AUTOSAR XML (schema 3.1.2)
package /Components/SWC_TPM
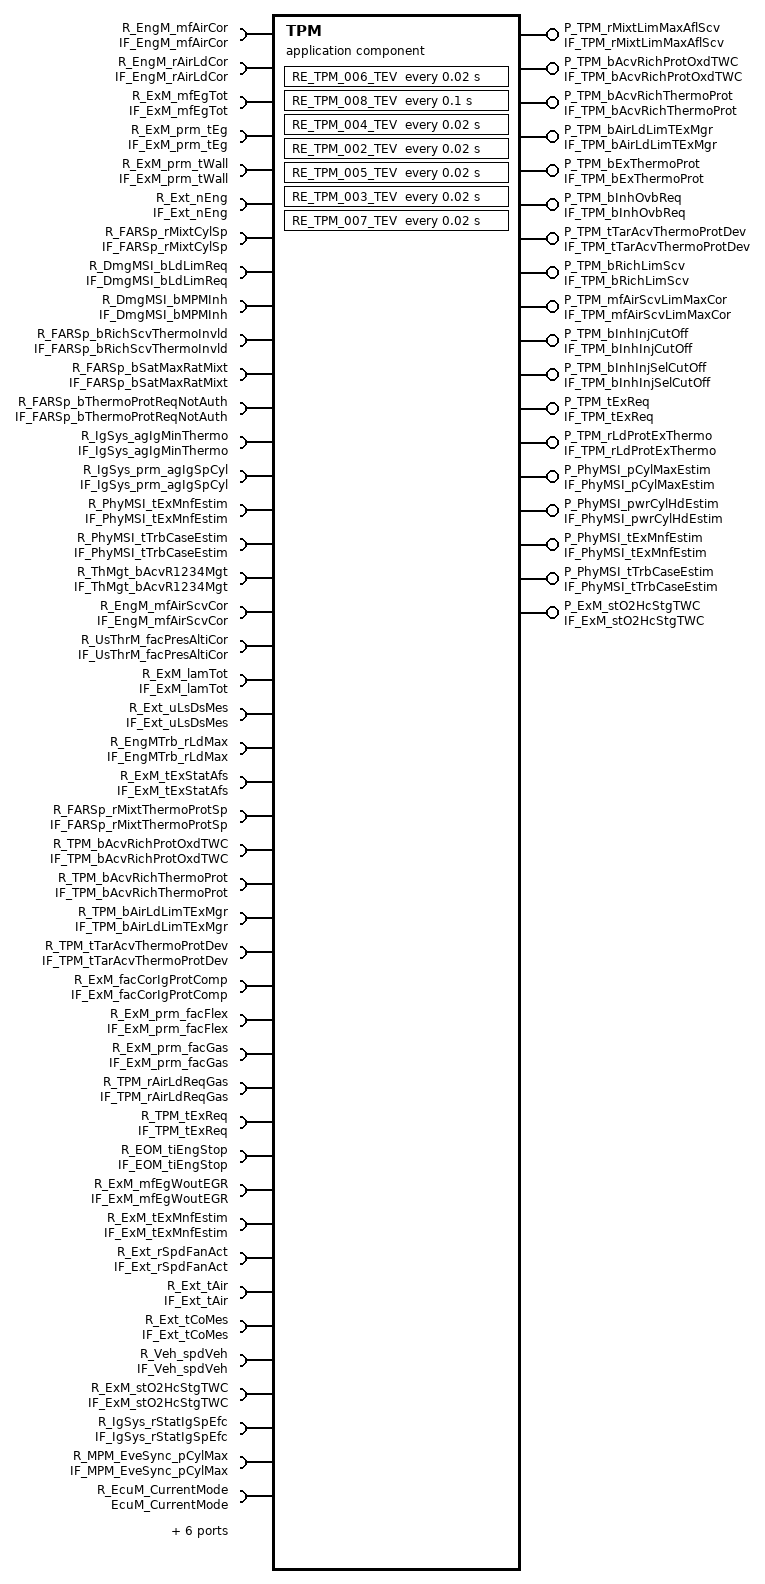
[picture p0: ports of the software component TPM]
  application software component type TPM
    50 x require port:
      R_EngM_mfAirCor: unqueued-receiver-com-spec{data-element=EngM_mfAirCor, init-value=ConstantValue, resync-time=0}, required-interface=IF_EngM_mfAirCor  # Receiver of interface IF_EngM_mfAirCor - Requirement Reference: [01552_11_02164-TPM-I002(0)]
      R_EngM_rAirLdCor: unqueued-receiver-com-spec{data-element=EngM_rAirLdCor, init-value=ConstantValue1, resync-time=0}, required-interface=IF_EngM_rAirLdCor  # Receiver of interface IF_EngM_rAirLdCor - Requirement Reference: [01552_11_02164-TPM-I003(0)]
      R_ExM_mfEgTot: unqueued-receiver-com-spec{data-element=ExM_mfEgTot, init-value=ConstantValue3, resync-time=0}, required-interface=IF_ExM_mfEgTot  # Receiver of interface IF_ExM_mfEgTot - Requirement Reference: [01552_11_02164-TPM-I004(0)]
      R_ExM_prm_tEg: unqueued-receiver-com-spec{data-element=ExM_prm_tEg, init-value=ArrayConstantValue, resync-time=0}, required-interface=IF_ExM_prm_tEg  # Receiver of interface IF_ExM_prm_tEg - Requirement Reference: [01552_11_02164-TPM-I005(0)]
      R_ExM_prm_tWall: unqueued-receiver-com-spec{data-element=ExM_prm_tWall, init-value=ArrayConstantValue5, resync-time=0}, required-interface=IF_ExM_prm_tWall  # Receiver of interface IF_ExM_prm_tWall - Requirement Reference: [01552_11_02164-TPM-I006(0)]
      R_Ext_nEng: unqueued-receiver-com-spec{data-element=Ext_nEng, init-value=ConstantValue7, resync-time=0}, required-interface=IF_Ext_nEng  # Receiver of interface IF_Ext_nEng - Requirement Reference: [01552_11_02164-TPM-I007(0)]
      R_FARSp_rMixtCylSp: unqueued-receiver-com-spec{data-element=FARSp_rMixtCylSp, init-value=ConstantValue9, resync-time=0}, required-interface=IF_FARSp_rMixtCylSp  # Receiver of interface IF_FARSp_rMixtCylSp - Requirement Reference: [01552_11_02164-TPM-I008(0)]
      R_DmgMSI_bLdLimReq: unqueued-receiver-com-spec{data-element=DmgMSI_bLdLimReq, init-value=ConstantValue11, resync-time=0}, required-interface=IF_DmgMSI_bLdLimReq  # Receiver of interface IF_DmgMSI_bLdLimReq - Requirement Reference: [01552_11_02164-TPM-I015(0)]
      R_DmgMSI_bMPMInh: unqueued-receiver-com-spec{data-element=DmgMSI_bMPMInh, init-value=ConstantValue13, resync-time=0}, required-interface=IF_DmgMSI_bMPMInh  # Receiver of interface IF_DmgMSI_bMPMInh - Requirement Reference: [01552_11_02164-TPM-I016(0)]
      R_FARSp_bRichScvThermoInvld: unqueued-receiver-com-spec{data-element=FARSp_bRichScvThermoInvld, init-value=ConstantValue15, resync-time=0}, required-interface=IF_FARSp_bRichScvThermoInvld  # Receiver of interface IF_FARSp_bRichScvThermoInvld - Requirement Reference: [01552_11_02164-TPM-I017(0)]
      R_FARSp_bSatMaxRatMixt: unqueued-receiver-com-spec{data-element=FARSp_bSatMaxRatMixt, init-value=ConstantValue17, resync-time=0}, required-interface=IF_FARSp_bSatMaxRatMixt  # Receiver of interface IF_FARSp_bSatMaxRatMixt - Requirement Reference: [01552_11_02164-TPM-I018(0)]
      R_FARSp_bThermoProtReqNotAuth: unqueued-receiver-com-spec{data-element=FARSp_bThermoProtReqNotAuth, init-value=ConstantValue19, resync-time=0}, required-interface=IF_FARSp_bThermoProtReqNotAuth  # Receiver of interface IF_FARSp_bThermoProtReqNotAuth - Requirement Reference: [01552_11_02164-TPM-I019(0)]
      R_IgSys_agIgMinThermo: unqueued-receiver-com-spec{data-element=IgSys_agIgMinThermo, init-value=ConstantValue21, resync-time=0}, required-interface=IF_IgSys_agIgMinThermo  # Receiver of interface IF_IgSys_agIgMinThermo - Requirement Reference: [01552_11_02164-TPM-I020(0)]
      R_IgSys_prm_agIgSpCyl: unqueued-receiver-com-spec{data-element=IgSys_prm_agIgSpCyl, init-value=ArrayConstantValue23, resync-time=0}, required-interface=IF_IgSys_prm_agIgSpCyl  # Receiver of interface IF_IgSys_prm_agIgSpCyl - Requirement Reference: [01552_11_02164-TPM-I021(0)]
      R_PhyMSI_tExMnfEstim: unqueued-receiver-com-spec{data-element=PhyMSI_tExMnfEstim, init-value=ConstantValue25, resync-time=0}, required-interface=IF_PhyMSI_tExMnfEstim  # Receiver of interface IF_PhyMSI_tExMnfEstim - Requirement Reference: [01552_11_02164-TPM-I022(0)]
      R_PhyMSI_tTrbCaseEstim: unqueued-receiver-com-spec{data-element=PhyMSI_tTrbCaseEstim, init-value=ConstantValue27, resync-time=0}, required-interface=IF_PhyMSI_tTrbCaseEstim  # Receiver of interface IF_PhyMSI_tTrbCaseEstim - Requirement Reference: [01552_11_02164-TPM-I023(0)]
      R_ThMgt_bAcvR1234Mgt: unqueued-receiver-com-spec{data-element=ThMgt_bAcvR1234Mgt, init-value=ConstantValue29, resync-time=0}, required-interface=IF_ThMgt_bAcvR1234Mgt  # Receiver of interface IF_ThMgt_bAcvR1234Mgt - Requirement Reference: [01552_11_02164-TPM-I024(0)]
      R_EngM_mfAirScvCor: unqueued-receiver-com-spec{data-element=EngM_mfAirScvCor, init-value=ConstantValue31, resync-time=0}, required-interface=IF_EngM_mfAirScvCor  # Receiver of interface IF_EngM_mfAirScvCor - Requirement Reference: [01552_11_02164-TPM-I027(0)]
      R_UsThrM_facPresAltiCor: unqueued-receiver-com-spec{data-element=UsThrM_facPresAltiCor, init-value=ConstantValue33, resync-time=0}, required-interface=IF_UsThrM_facPresAltiCor  # Receiver of interface IF_UsThrM_facPresAltiCor - Requirement Reference: [01552_11_02164-TPM-I028(0)]
      R_ExM_lamTot: unqueued-receiver-com-spec{data-element=ExM_lamTot, init-value=ConstantValue35, resync-time=0}, required-interface=IF_ExM_lamTot  # Receiver of interface IF_ExM_lamTot - Requirement Reference: [01552_11_02164-TPM-I031(0)]
      R_Ext_uLsDsMes: unqueued-receiver-com-spec{data-element=Ext_uLsDsMes, init-value=ConstantValue37, resync-time=0}, required-interface=IF_Ext_uLsDsMes  # Receiver of interface IF_Ext_uLsDsMes - Requirement Reference: [01552_11_02164-TPM-I032(0)]
      R_EngMTrb_rLdMax: unqueued-receiver-com-spec{data-element=EngMTrb_rLdMax, init-value=ConstantValue39, resync-time=0}, required-interface=IF_EngMTrb_rLdMax  # Receiver of interface IF_EngMTrb_rLdMax - Requirement Reference: [01552_11_02164-TPM-I035(0)]
      R_ExM_tExStatAfs: unqueued-receiver-com-spec{data-element=ExM_tExStatAfs, init-value=ConstantValue41, resync-time=0}, required-interface=IF_ExM_tExStatAfs  # Receiver of interface IF_ExM_tExStatAfs - Requirement Reference: [01552_11_02164-TPM-I036(1)]
      R_FARSp_rMixtThermoProtSp: unqueued-receiver-com-spec{data-element=FARSp_rMixtThermoProtSp, init-value=ConstantValue43, resync-time=0}, required-interface=IF_FARSp_rMixtThermoProtSp  # Receiver of interface IF_FARSp_rMixtThermoProtSp - Requirement Reference: [01552_11_02164-TPM-I037(0)]
      R_TPM_bAcvRichProtOxdTWC: unqueued-receiver-com-spec{data-element=TPM_bAcvRichProtOxdTWC, init-value=ConstantValue45, resync-time=0}, required-interface=IF_TPM_bAcvRichProtOxdTWC  # Receiver of interface IF_TPM_bAcvRichProtOxdTWC - Requirement Reference: [01552_11_02164-TPM-I038(0)]
      R_TPM_bAcvRichThermoProt: unqueued-receiver-com-spec{data-element=TPM_bAcvRichThermoProt, init-value=ConstantValue47, resync-time=0}, required-interface=IF_TPM_bAcvRichThermoProt  # Receiver of interface IF_TPM_bAcvRichThermoProt - Requirement Reference: [01552_11_02164-TPM-I039(0)]
      R_TPM_bAirLdLimTExMgr: unqueued-receiver-com-spec{data-element=TPM_bAirLdLimTExMgr, init-value=ConstantValue49, resync-time=0}, required-interface=IF_TPM_bAirLdLimTExMgr  # Receiver of interface IF_TPM_bAirLdLimTExMgr - Requirement Reference: [01552_11_02164-TPM-I040(0)]
      R_TPM_tTarAcvThermoProtDev: unqueued-receiver-com-spec{data-element=TPM_tTarAcvThermoProtDev, init-value=ConstantValue51, resync-time=0}, required-interface=IF_TPM_tTarAcvThermoProtDev  # Receiver of interface IF_TPM_tTarAcvThermoProtDev - Requirement Reference: [01552_11_02164-TPM-I041(1)]
      R_ExM_facCorIgProtComp: unqueued-receiver-com-spec{data-element=ExM_facCorIgProtComp, init-value=ConstantValue53, resync-time=0}, required-interface=IF_ExM_facCorIgProtComp  # Receiver of interface IF_ExM_facCorIgProtComp - Requirement Reference: [01552_11_02164-TPM-I043(0)]
      R_ExM_prm_facFlex: unqueued-receiver-com-spec{data-element=ExM_prm_facFlex, init-value=ArrayConstantValue55, resync-time=0}, required-interface=IF_ExM_prm_facFlex  # Receiver of interface IF_ExM_prm_facFlex - Requirement Reference: [01552_11_02164-TPM-I045(0)]
      R_ExM_prm_facGas: unqueued-receiver-com-spec{data-element=ExM_prm_facGas, init-value=ArrayConstantValue57, resync-time=0}, required-interface=IF_ExM_prm_facGas  # Receiver of interface IF_ExM_prm_facGas - Requirement Reference: [01552_11_02164-TPM-I046(0)]
      R_TPM_rAirLdReqGas: unqueued-receiver-com-spec{data-element=TPM_rAirLdReqGas, init-value=ConstantValue59, resync-time=0}, required-interface=IF_TPM_rAirLdReqGas  # Receiver of interface IF_TPM_rAirLdReqGas - Requirement Reference: [01552_11_02164-TPM-I050(0)]
      R_TPM_tExReq: unqueued-receiver-com-spec{data-element=TPM_tExReq, init-value=ConstantValue61, resync-time=0}, required-interface=IF_TPM_tExReq  # Receiver of interface IF_TPM_tExReq - Requirement Reference: [01552_11_02164-TPM-I051(1)]
      R_EOM_tiEngStop: unqueued-receiver-com-spec{data-element=EOM_tiEngStop, init-value=ConstantValue63, resync-time=0}, required-interface=IF_EOM_tiEngStop  # Receiver of interface IF_EOM_tiEngStop - Requirement Reference: [01552_11_02164-TPM-I056(0)]
      R_ExM_mfEgWoutEGR: unqueued-receiver-com-spec{data-element=ExM_mfEgWoutEGR, init-value=ConstantValue65, resync-time=0}, required-interface=IF_ExM_mfEgWoutEGR  # Receiver of interface IF_ExM_mfEgWoutEGR - Requirement Reference: [01552_11_02164-TPM-I057(0)]
      R_ExM_tExMnfEstim: unqueued-receiver-com-spec{data-element=ExM_tExMnfEstim, init-value=ConstantValue67, resync-time=0}, required-interface=IF_ExM_tExMnfEstim  # Receiver of interface IF_ExM_tExMnfEstim - Requirement Reference: [01552_11_02164-TPM-I058(0)]
      R_Ext_rSpdFanAct: unqueued-receiver-com-spec{data-element=Ext_rSpdFanAct, init-value=ConstantValue69, resync-time=0}, required-interface=IF_Ext_rSpdFanAct  # Receiver of interface IF_Ext_rSpdFanAct - Requirement Reference: [01552_11_02164-TPM-I059(0)]
      R_Ext_tAir: unqueued-receiver-com-spec{data-element=Ext_tAir, init-value=ConstantValue71, resync-time=0}, required-interface=IF_Ext_tAir  # Receiver of interface IF_Ext_tAir - Requirement Reference: [01552_11_02164-TPM-I060(0)]
      R_Ext_tCoMes: unqueued-receiver-com-spec{data-element=Ext_tCoMes, init-value=ConstantValue73, resync-time=0}, required-interface=IF_Ext_tCoMes  # Receiver of interface IF_Ext_tCoMes - Requirement Reference: [01552_11_02164-TPM-I061(0)]
      R_Veh_spdVeh: unqueued-receiver-com-spec{data-element=Veh_spdVeh, init-value=ConstantValue75, resync-time=0}, required-interface=IF_Veh_spdVeh  # Receiver of interface IF_Veh_spdVeh - Requirement Reference: [01552_11_02164-TPM-I062(0)]
      R_ExM_stO2HcStgTWC: unqueued-receiver-com-spec{data-element=ExM_stO2HcStgTWC, init-value=ConstantValue77, resync-time=0}, required-interface=IF_ExM_stO2HcStgTWC  # Receiver of interface IF_ExM_stO2HcStgTWC - Requirement Reference: [01552_11_02164-TPM-I083(0)]
      R_IgSys_rStatIgSpEfc: unqueued-receiver-com-spec{data-element=IgSys_rStatIgSpEfc, init-value=ConstantValue79, resync-time=0}, required-interface=IF_IgSys_rStatIgSpEfc  # Receiver of interface IF_IgSys_rStatIgSpEfc - Requirement Reference: [01552_11_02164-TPM-I085(0)]
      R_MPM_EveSync_pCylMax: unqueued-receiver-com-spec{data-element=MPM_EveSync_pCylMax, init-value=ConstantValue81, resync-time=0}, required-interface=IF_MPM_EveSync_pCylMax  # Receiver of interface IF_MPM_EveSync_pCylMax - Requirement Reference: [01552_11_02164-TPM-I086(0)]
      R_EcuM_CurrentMode: required-interface=EcuM_CurrentMode
      R_UCE_stWkuMainRelSt: required-interface=IF_UCE_stWkuMainRelSt
      R_FRM_bAcvEcpHeatProt: required-interface=FunctionInhibition  # 01552_11_02164-TPM-I076(0)
      R_FRM_bAcvTPMDecTMaxDev: required-interface=FunctionInhibition  # 01552_11_02164-TPM-I077(0)
      R_FRM_bAcvLimScv: required-interface=FunctionInhibition  # 01552_11_02164-TPM-I078(0)
      R_FRM_bAcvTPMInhLsTWCSt: required-interface=FunctionInhibition  # 01552_11_02164-TPM-I079(0)
      R_FRM_bInhCutOff: required-interface=FunctionInhibition  # 01552_11_02164-TPM-I080(0)
    18 x provide port:
      P_TPM_rMixtLimMaxAflScv: unqueued-sender-com-spec{data-element=TPM_rMixtLimMaxAflScv, can-invalidate=false, init-value=ConstantValue83}, provided-interface=IF_TPM_rMixtLimMaxAflScv
      P_TPM_bAcvRichProtOxdTWC: unqueued-sender-com-spec{data-element=TPM_bAcvRichProtOxdTWC, can-invalidate=false, init-value=ConstantValue85}, provided-interface=IF_TPM_bAcvRichProtOxdTWC
      P_TPM_bAcvRichThermoProt: unqueued-sender-com-spec{data-element=TPM_bAcvRichThermoProt, can-invalidate=false, init-value=ConstantValue87}, provided-interface=IF_TPM_bAcvRichThermoProt
      P_TPM_bAirLdLimTExMgr: unqueued-sender-com-spec{data-element=TPM_bAirLdLimTExMgr, can-invalidate=false, init-value=ConstantValue89}, provided-interface=IF_TPM_bAirLdLimTExMgr
      P_TPM_bExThermoProt: unqueued-sender-com-spec{data-element=TPM_bExThermoProt, can-invalidate=false, init-value=ConstantValue91}, provided-interface=IF_TPM_bExThermoProt
      P_TPM_bInhOvbReq: unqueued-sender-com-spec{data-element=TPM_bInhOvbReq, can-invalidate=false, init-value=ConstantValue93}, provided-interface=IF_TPM_bInhOvbReq
      P_TPM_tTarAcvThermoProtDev: unqueued-sender-com-spec{data-element=TPM_tTarAcvThermoProtDev, can-invalidate=false, init-value=TPM_tTarAcvThermoProtDev_Cst}, provided-interface=IF_TPM_tTarAcvThermoProtDev
      P_TPM_bRichLimScv: unqueued-sender-com-spec{data-element=TPM_bRichLimScv, can-invalidate=false, init-value=ConstantValue95}, provided-interface=IF_TPM_bRichLimScv
      P_TPM_mfAirScvLimMaxCor: unqueued-sender-com-spec{data-element=TPM_mfAirScvLimMaxCor, can-invalidate=false, init-value=TPM_mfAirScvLimMaxCor_Cst}, provided-interface=IF_TPM_mfAirScvLimMaxCor
      P_TPM_bInhInjCutOff: unqueued-sender-com-spec{data-element=TPM_bInhInjCutOff, can-invalidate=false, init-value=TPM_bInhInjCutOff_Cst}, provided-interface=IF_TPM_bInhInjCutOff
      P_TPM_bInhInjSelCutOff: unqueued-sender-com-spec{data-element=TPM_bInhInjSelCutOff, can-invalidate=false, init-value=TPM_bInhInjSelCutOff_Cst}, provided-interface=IF_TPM_bInhInjSelCutOff
      P_TPM_tExReq: unqueued-sender-com-spec{data-element=TPM_tExReq, can-invalidate=false, init-value=ConstantValue97}, provided-interface=IF_TPM_tExReq
      P_TPM_rLdProtExThermo: unqueued-sender-com-spec{data-element=TPM_rLdProtExThermo, can-invalidate=false, init-value=ConstantValue99}, provided-interface=IF_TPM_rLdProtExThermo
      P_PhyMSI_pCylMaxEstim: unqueued-sender-com-spec{data-element=PhyMSI_pCylMaxEstim, can-invalidate=false, init-value=ConstantValue101}, provided-interface=IF_PhyMSI_pCylMaxEstim
      P_PhyMSI_pwrCylHdEstim: unqueued-sender-com-spec{data-element=PhyMSI_pwrCylHdEstim, can-invalidate=false, init-value=ConstantValue103}, provided-interface=IF_PhyMSI_pwrCylHdEstim
      P_PhyMSI_tExMnfEstim: unqueued-sender-com-spec{data-element=PhyMSI_tExMnfEstim, can-invalidate=false, init-value=ConstantValue105}, provided-interface=IF_PhyMSI_tExMnfEstim
      P_PhyMSI_tTrbCaseEstim: unqueued-sender-com-spec{data-element=PhyMSI_tTrbCaseEstim, can-invalidate=false, init-value=ConstantValue107}, provided-interface=IF_PhyMSI_tTrbCaseEstim
      P_ExM_stO2HcStgTWC: unqueued-sender-com-spec{data-element=ExM_stO2HcStgTWC, can-invalidate=false, init-value=ConstantValue109}, provided-interface=IF_ExM_stO2HcStgTWC
  69 x constant specification:
    ArrayConstantValue
      value:
        array specification ArrayConstantValue: type=rt_Array_UInt16_12_m0
          12 x integer literal, all with type=DT_ExM_prm_tEg, value=0:
            Const
            Const{1..11}
    ArrayConstantValue23
      value:
        array specification ArrayConstantValue23: type=rt_Array_UInt8_6_m1
          6 x integer literal, all with type=DT_IgSys_prm_agIgSpCyl, value=96:
            Const
            Const{1..5}
    ArrayConstantValue5
      value:
        array specification ArrayConstantValue5: type=rt_Array_UInt16_12_m1
          12 x integer literal, all with type=DT_ExM_prm_tWall, value=0:
            Const
            Const{1..11}
    ArrayConstantValue55
      value:
        array specification ArrayConstantValue55: type=rt_Array_UInt16_5_m0
          5 x integer literal, all with type=DT_ExM_prm_facFlex, value=0:
            Const
            Const{1..4}
    ArrayConstantValue57
      value:
        array specification ArrayConstantValue57: type=Array_5_UInt16
          5 x integer literal, all with type=DT_ExM_prm_facGas, value=0:
            Const
            Const{1..4}
    ConstantValue
      value:
        integer literal ConstantValue: type=DT_EngM_mfAirCor, value=0
    ConstantValue1
      value:
        integer literal ConstantValue1: type=DT_EngM_rAirLdCor, value=0
    ConstantValue101
      value:
        integer literal ConstantValue101: type=DT_PhyMSI_pCylMaxEstim, value=0
    ConstantValue103
      value:
        integer literal ConstantValue103: type=DT_PhyMSI_pwrCylHdEstim, value=0
    ConstantValue105
      value:
        integer literal ConstantValue105: type=DT_PhyMSI_tExMnfEstim, value=7136
    ConstantValue107
      value:
        integer literal ConstantValue107: type=DT_PhyMSI_tTrbCaseEstim, value=7136
    ConstantValue109
      value:
        integer literal ConstantValue109: type=DT_ExM_stO2HcStgTWC, value=0
    ConstantValue11
      value:
        boolean literal ConstantValue11: type=DT_DmgMSI_bLdLimReq, value=false
    ConstantValue13
      value:
        boolean literal ConstantValue13: type=DT_DmgMSI_bMPMInh, value=false
    ConstantValue15
      value:
        boolean literal ConstantValue15: type=DT_FARSp_bRichScvThermoInvld, value=false
    ConstantValue17
      value:
        boolean literal ConstantValue17: type=DT_FARSp_bSatMaxRatMixt, value=false
    ConstantValue19
      value:
        boolean literal ConstantValue19: type=DT_FARSp_bThermoProtReqNotAuth, value=false
    ConstantValue21
      value:
        integer literal ConstantValue21: type=DT_IgSys_agIgMinThermo, value=96
    ConstantValue25
      value:
        integer literal ConstantValue25: type=DT_PhyMSI_tExMnfEstim, value=7136
    ConstantValue27
      value:
        integer literal ConstantValue27: type=DT_PhyMSI_tTrbCaseEstim, value=7136
    ConstantValue29
      value:
        boolean literal ConstantValue29: type=DT_ThMgt_bAcvR1234Mgt, value=false
    ConstantValue3
      value:
        integer literal ConstantValue3: type=DT_ExM_mfEgTot, value=0
    ConstantValue31
      value:
        integer literal ConstantValue31: type=DT_EngM_mfAirScvCor, value=0
    ConstantValue33
      value:
        integer literal ConstantValue33: type=DT_UsThrM_facPresAltiCor, value=0
    ConstantValue35
      value:
        integer literal ConstantValue35: type=DT_ExM_lamTot, value=8192
    ConstantValue37
      value:
        integer literal ConstantValue37: type=DT_Ext_uLsDsMes, value=0
    ConstantValue39
      value:
        integer literal ConstantValue39: type=DT_EngMTrb_rLdMax, value=0
    ConstantValue41
      value:
        integer literal ConstantValue41: type=DT_ExM_tExStatAfs, value=4800
    ConstantValue43
      value:
        integer literal ConstantValue43: type=DT_FARSp_rMixtThermoProtSp, value=0
    ConstantValue45
      value:
        boolean literal ConstantValue45: type=DT_TPM_bAcvRichProtOxdTWC, value=false
    ConstantValue47
      value:
        boolean literal ConstantValue47: type=DT_TPM_bAcvRichThermoProt, value=false
    ConstantValue49
      value:
        boolean literal ConstantValue49: type=DT_TPM_bAirLdLimTExMgr, value=false
    ConstantValue51
      value:
        integer literal ConstantValue51: type=DT_TPM_tTarAcvThermoProtDev, value=7136
    ConstantValue53
      value:
        integer literal ConstantValue53: type=DT_ExM_facCorIgProtComp, value=16384
    ConstantValue59
      value:
        integer literal ConstantValue59: type=DT_TPM_rAirLdReqGas, value=49152
    ConstantValue61
      value:
        integer literal ConstantValue61: type=DT_TPM_tExReq, value=7136
    ConstantValue63
      value:
        integer literal ConstantValue63: type=DT_EOM_tiEngStop, value=864000
    ConstantValue65
      value:
        integer literal ConstantValue65: type=DT_ExM_mfEgWoutEGR, value=0
    ConstantValue67
      value:
        integer literal ConstantValue67: type=DT_ExM_tExMnfEstim, value=4800
    ConstantValue69
      value:
        integer literal ConstantValue69: type=DT_Ext_rSpdFanAct, value=0
    ConstantValue7
      value:
        integer literal ConstantValue7: type=DT_Ext_nEng, value=0
    ConstantValue71
      value:
        integer literal ConstantValue71: type=DT_Ext_tAir, value=20
    ConstantValue73
      value:
        integer literal ConstantValue73: type=DT_Ext_tCoMes, value=20
    ConstantValue75
      value:
        integer literal ConstantValue75: type=DT_Veh_spdVeh, value=0
    ConstantValue77
      value:
        integer literal ConstantValue77: type=DT_ExM_stO2HcStgTWC, value=0
    ConstantValue79
      value:
        integer literal ConstantValue79: type=DT_IgSys_rStatIgSpEfc, value=0
    ConstantValue81
      value:
        boolean literal ConstantValue81: type=DT_MPM_EveSync_pCylMax, value=false
    ConstantValue83
      value:
        integer literal ConstantValue83: type=DT_TPM_rMixtLimMaxAflScv, value=0
    ConstantValue85
      value:
        boolean literal ConstantValue85: type=DT_TPM_bAcvRichProtOxdTWC, value=false
    ConstantValue87
      value:
        boolean literal ConstantValue87: type=DT_TPM_bAcvRichThermoProt, value=false
    ConstantValue89
      value:
        boolean literal ConstantValue89: type=DT_TPM_bAirLdLimTExMgr, value=false
    ConstantValue9
      value:
        integer literal ConstantValue9: type=DT_FARSp_rMixtCylSp, value=4096
    ConstantValue91
      value:
        boolean literal ConstantValue91: type=DT_TPM_bExThermoProt, value=false
    ConstantValue93
      value:
        boolean literal ConstantValue93: type=DT_TPM_bInhOvbReq, value=false
    ConstantValue95
      value:
        boolean literal ConstantValue95: type=DT_TPM_bRichLimScv, value=false
    ConstantValue97
      value:
        integer literal ConstantValue97: type=DT_TPM_tExReq, value=7136
    ConstantValue99
      value:
        integer literal ConstantValue99: type=DT_TPM_rLdProtExThermo, value=0
    TPM_bAcvProtExScv_Cst
      value:
        boolean literal TPM_bAcvProtExScv_Cst: type=DT_TPM_bAcvProtExScv, value=false
    TPM_bInhInjCutOff_Cst
      value:
        boolean literal TPM_bInhInjCutOff_Cst: type=DT_TPM_bInhInjCutOff, value=false
    TPM_bInhInjSelCutOff_Cst
      value:
        boolean literal TPM_bInhInjSelCutOff_Cst: type=DT_TPM_bInhInjSelCutOff, value=false
    TPM_mfAirScvLimMax_Cst
      value:
        integer literal TPM_mfAirScvLimMax_Cst: type=DT_TPM_mfAirScvLimMax, value=0
    TPM_mfAirScvLimMaxCor_Cst
      value:
        integer literal TPM_mfAirScvLimMaxCor_Cst: type=DT_TPM_mfAirScvLimMaxCor, value=0
    TPM_noAcvThermoProtDev_Cst
      value:
        integer literal TPM_noAcvThermoProtDev_Cst: type=DT_TPM_noAcvThermoProtDev, value=0
    TPM_rAirLdReq_Cst
      value:
        integer literal TPM_rAirLdReq_Cst: type=DT_TPM_rAirLdReq, value=0
    TPM_rAirLdReqRbl_Cst
      value:
        integer literal TPM_rAirLdReqRbl_Cst: type=DT_TPM_rAirLdReqRbl, value=0
    TPM_tExCurAcvThermoProtDev_Cst
      value:
        integer literal TPM_tExCurAcvThermoProtDev_Cst: type=DT_TPM_tExCurAcvThermoProtDev, value=0
    TPM_tRefTWCScvMax_Cst
      value:
        integer literal TPM_tRefTWCScvMax_Cst: type=DT_TPM_tRefTWCScvMax, value=0
    TPM_tTarAcvThermoProtDev_Cst
      value:
        integer literal TPM_tTarAcvThermoProtDev_Cst: type=DT_TPM_tTarAcvThermoProtDev, value=7136
    TPM_tTWC_Cst
      value:
        integer literal TPM_tTWC_Cst: type=DT_TPM_tTWC, value=0
  internal behavior IB_TPM: component=TPM
    timing event EV_TPM_006_TEV: mode-dependency=dependent-on-mode=[R_UCE_stWkuMainRelSt.RCD_stWkuMainRelSt.Invalid, R_UCE_stWkuMainRelSt.RCD_stWkuMainRelSt.PostMainWakeUp, R_UCE_stWkuMainRelSt.RCD_stWkuMainRelSt.PreMainWakeUp], start-on-event=RE_TPM_006_TEV, period=0.02
    timing event EV_TPM_008_TEV: mode-dependency=dependent-on-mode=[R_UCE_stWkuMainRelSt.RCD_stWkuMainRelSt.Invalid, R_UCE_stWkuMainRelSt.RCD_stWkuMainRelSt.PostMainWakeUp, R_UCE_stWkuMainRelSt.RCD_stWkuMainRelSt.PreMainWakeUp], start-on-event=RE_TPM_008_TEV, period=0.1
    data received event EV_TPM_009_DRE: start-on-event=RE_TPM_009_DRE, data=R_MPM_EveSync_pCylMax.MPM_EveSync_pCylMax
    timing event EV_TPM_004_TEV: mode-dependency=dependent-on-mode=[R_UCE_stWkuMainRelSt.RCD_stWkuMainRelSt.Invalid, R_UCE_stWkuMainRelSt.RCD_stWkuMainRelSt.PostMainWakeUp, R_UCE_stWkuMainRelSt.RCD_stWkuMainRelSt.PreMainWakeUp], start-on-event=RE_TPM_004_TEV, period=0.02
    timing event EV_TPM_002_TEV: mode-dependency=dependent-on-mode=[R_UCE_stWkuMainRelSt.RCD_stWkuMainRelSt.Invalid, R_UCE_stWkuMainRelSt.RCD_stWkuMainRelSt.PostMainWakeUp, R_UCE_stWkuMainRelSt.RCD_stWkuMainRelSt.PreMainWakeUp], start-on-event=RE_TPM_002_TEV, period=0.02
    timing event EV_TPM_005_TEV: mode-dependency=dependent-on-mode=[R_UCE_stWkuMainRelSt.RCD_stWkuMainRelSt.Invalid, R_UCE_stWkuMainRelSt.RCD_stWkuMainRelSt.PostMainWakeUp, R_UCE_stWkuMainRelSt.RCD_stWkuMainRelSt.PreMainWakeUp], start-on-event=RE_TPM_005_TEV, period=0.02
    mode switch event EV_TPM_001_MSE: start-on-event=RE_TPM_001_MSE, activation=ENTRY, mode=R_EcuM_CurrentMode.currentMode.RUN
    timing event EV_TPM_003_TEV: mode-dependency=dependent-on-mode=[R_UCE_stWkuMainRelSt.RCD_stWkuMainRelSt.Invalid, R_UCE_stWkuMainRelSt.RCD_stWkuMainRelSt.PostMainWakeUp, R_UCE_stWkuMainRelSt.RCD_stWkuMainRelSt.PreMainWakeUp], start-on-event=RE_TPM_003_TEV, period=0.02
    timing event EV_TPM_007_TEV: mode-dependency=dependent-on-mode=[R_UCE_stWkuMainRelSt.RCD_stWkuMainRelSt.Invalid, R_UCE_stWkuMainRelSt.RCD_stWkuMainRelSt.PostMainWakeUp, R_UCE_stWkuMainRelSt.RCD_stWkuMainRelSt.PreMainWakeUp], start-on-event=RE_TPM_007_TEV, period=0.02
    8 x inter runnable variable, all with sw-calibration-access=READ-WRITE, communication-approach=EXPLICIT:
      TPM_tExCurAcvThermoProtDev: type=DT_TPM_tExCurAcvThermoProtDev, init-value=TPM_tExCurAcvThermoProtDev_Cst  # [01552_11_02164-TPM-I066(0)] - In danger element's temperature
      TPM_mfAirScvLimMax: type=DT_TPM_mfAirScvLimMax, init-value=TPM_mfAirScvLimMax_Cst  # [01552_11_02164-TPM-I063(0)] - Maximum scavenging air mass flow for three way catalyst thermal and oxydation protection
      TPM_rAirLdReqRbl: type=DT_TPM_rAirLdReqRbl, init-value=TPM_rAirLdReqRbl_Cst  # [01552_11_02164-TPM-I069(0)] - Air load limitation due to rumble risk
      TPM_tTWC: type=DT_TPM_tTWC, init-value=TPM_tTWC_Cst  # [01552_11_02164-TPM-I067(0)] - Catalyst's temperature
      TPM_noAcvThermoProtDev: type=DT_TPM_noAcvThermoProtDev, init-value=TPM_noAcvThermoProtDev_Cst  # [01552_11_02164-TPM-I065(0)] - In danger element's identification number
      TPM_rAirLdReq: type=DT_TPM_rAirLdReq, init-value=TPM_rAirLdReq_Cst  # [01552_11_02164-TPM-I070(0)] - Air Load limitation due to component protection
      TPM_bAcvProtExScv: type=DT_TPM_bAcvProtExScv, init-value=TPM_bAcvProtExScv_Cst  # [01552_11_02164-TPM-I068(0)] - Boolean indicating the activation of scavenging inhibition
      TPM_tRefTWCScvMax: type=DT_TPM_tRefTWCScvMax, init-value=TPM_tRefTWCScvMax_Cst  # [01552_11_02164-TPM-I064(0)] - Reference TWC temperature for maximum scavenging air mass flow limitation
    9 x runnable:
      RE_TPM_003_TEV: written-variable=[TPM_noAcvThermoProtDev, TPM_tExCurAcvThermoProtDev, TPM_tTWC]  # 01552_11_02164-TPM-A003(0)
        13 x data receive point:
          dr_ThMgt_bAcvR1234Mgt: data-element=R_ThMgt_bAcvR1234Mgt.ThMgt_bAcvR1234Mgt
          dr_PhyMSI_tTrbCaseEstim: data-element=R_PhyMSI_tTrbCaseEstim.PhyMSI_tTrbCaseEstim
          dr_PhyMSI_tExMnfEstim: data-element=R_PhyMSI_tExMnfEstim.PhyMSI_tExMnfEstim
          dr_FARSp_rMixtCylSp: data-element=R_FARSp_rMixtCylSp.FARSp_rMixtCylSp
          dr_DmgMSI_bMPMInh: data-element=R_DmgMSI_bMPMInh.DmgMSI_bMPMInh
          dr_ExM_prm_tEg: data-element=R_ExM_prm_tEg.ExM_prm_tEg
          dr_FARSp_bRichScvThermoInvld: data-element=R_FARSp_bRichScvThermoInvld.FARSp_bRichScvThermoInvld
          dr_ExM_prm_tWall: data-element=R_ExM_prm_tWall.ExM_prm_tWall
          dr_FARSp_bSatMaxRatMixt: data-element=R_FARSp_bSatMaxRatMixt.FARSp_bSatMaxRatMixt
          dr_IgSys_agIgMinThermo: data-element=R_IgSys_agIgMinThermo.IgSys_agIgMinThermo
          dr_FARSp_bThermoProtReqNotAuth: data-element=R_FARSp_bThermoProtReqNotAuth.FARSp_bThermoProtReqNotAuth
          dr_DmgMSI_bLdLimReq: data-element=R_DmgMSI_bLdLimReq.DmgMSI_bLdLimReq
          dr_IgSys_prm_agIgSpCyl: data-element=R_IgSys_prm_agIgSpCyl.IgSys_prm_agIgSpCyl
        6 x data send point:
          ds_TPM_bInhOvbReq: data-element=P_TPM_bInhOvbReq.TPM_bInhOvbReq
          ds_TPM_bAcvRichThermoProt: data-element=P_TPM_bAcvRichThermoProt.TPM_bAcvRichThermoProt
          ds_TPM_bAcvRichProtOxdTWC: data-element=P_TPM_bAcvRichProtOxdTWC.TPM_bAcvRichProtOxdTWC
          ds_TPM_bAirLdLimTExMgr: data-element=P_TPM_bAirLdLimTExMgr.TPM_bAirLdLimTExMgr
          ds_TPM_tTarAcvThermoProtDev: data-element=P_TPM_tTarAcvThermoProtDev.TPM_tTarAcvThermoProtDev
          ds_TPM_bExThermoProt: data-element=P_TPM_bExThermoProt.TPM_bExThermoProt
        sync call SC_FRM_bAcvEcpHeatProt: operation=R_FRM_bAcvEcpHeatProt.GetFunctionPermission
        sync call SC_FRM_bAcvTPMDecTMaxDev: operation=R_FRM_bAcvTPMDecTMaxDev.GetFunctionPermission
      RE_TPM_005_TEV: read-variable=TPM_tTWC  # 01552_11_02164-TPM-A005(0)
        5 x data receive point:
          dr_EngM_mfAirCor: data-element=R_EngM_mfAirCor.EngM_mfAirCor
          dr_EngM_mfAirScvCor: data-element=R_EngM_mfAirScvCor.EngM_mfAirScvCor
          dr_FARSp_rMixtCylSp: data-element=R_FARSp_rMixtCylSp.FARSp_rMixtCylSp
          dr_ExM_lamTot: data-element=R_ExM_lamTot.ExM_lamTot
          dr_Ext_uLsDsMes: data-element=R_Ext_uLsDsMes.Ext_uLsDsMes
        data send point ds_TPM_bInhInjCutOff: data-element=P_TPM_bInhInjCutOff.TPM_bInhInjCutOff
        data send point ds_TPM_bInhInjSelCutOff: data-element=P_TPM_bInhInjSelCutOff.TPM_bInhInjSelCutOff
        data send point ds_ExM_stO2HcStgTWC: data-element=P_ExM_stO2HcStgTWC.ExM_stO2HcStgTWC
        sync call SC_FRM_bInhCutOff: operation=R_FRM_bInhCutOff.GetFunctionPermission
        sync call SC_FRM_bAcvTPMDecTMaxDev: operation=R_FRM_bAcvTPMDecTMaxDev.GetFunctionPermission
        sync call SC_FRM_bAcvTPMInhLsTWCSt: operation=R_FRM_bAcvTPMInhLsTWCSt.GetFunctionPermission
      RE_TPM_002_TEV: written-variable=[TPM_tRefTWCScvMax, TPM_mfAirScvLimMax]  # 01552_11_02164-TPM-A002(0)
        8 x data receive point:
          dr_EngM_rAirLdCor: data-element=R_EngM_rAirLdCor.EngM_rAirLdCor
          dr_ExM_prm_tWall: data-element=R_ExM_prm_tWall.ExM_prm_tWall
          dr_FARSp_rMixtCylSp: data-element=R_FARSp_rMixtCylSp.FARSp_rMixtCylSp
          dr_ExM_prm_tEg: data-element=R_ExM_prm_tEg.ExM_prm_tEg
          dr_EngM_mfAirCor: data-element=R_EngM_mfAirCor.EngM_mfAirCor
          dr_ExM_mfEgTot: data-element=R_ExM_mfEgTot.ExM_mfEgTot
          dr_ExM_stO2HcStgTWC: data-element=R_ExM_stO2HcStgTWC.ExM_stO2HcStgTWC
          dr_Ext_nEng: data-element=R_Ext_nEng.Ext_nEng
        data send point ds_TPM_rMixtLimMaxAflScv: data-element=P_TPM_rMixtLimMaxAflScv.TPM_rMixtLimMaxAflScv
      RE_TPM_004_TEV: read-variable=[TPM_mfAirScvLimMax, TPM_tRefTWCScvMax], written-variable=[TPM_bAcvProtExScv, TPM_rAirLdReqRbl]  # 01552_11_02164-TPM-A004(0)
        6 x data receive point:
          dr_EngM_rAirLdCor: data-element=R_EngM_rAirLdCor.EngM_rAirLdCor
          dr_ExM_stO2HcStgTWC: data-element=R_ExM_stO2HcStgTWC.ExM_stO2HcStgTWC
          dr_EngM_mfAirScvCor: data-element=R_EngM_mfAirScvCor.EngM_mfAirScvCor
          dr_UsThrM_facPresAltiCor: data-element=R_UsThrM_facPresAltiCor.UsThrM_facPresAltiCor
          dr_Ext_nEng: data-element=R_Ext_nEng.Ext_nEng
          dr_FARSp_bRichScvThermoInvld: data-element=R_FARSp_bRichScvThermoInvld.FARSp_bRichScvThermoInvld
        data send point ds_TPM_mfAirScvLimMaxCor: data-element=P_TPM_mfAirScvLimMaxCor.TPM_mfAirScvLimMaxCor
        data send point ds_TPM_bRichLimScv: data-element=P_TPM_bRichLimScv.TPM_bRichLimScv
        sync call SC_FRM_bAcvTPMDecTMaxDev: operation=R_FRM_bAcvTPMDecTMaxDev.GetFunctionPermission
        sync call SC_FRM_bAcvLimScv: operation=R_FRM_bAcvLimScv.GetFunctionPermission
      RE_TPM_008_TEV  # 01552_11_02164-TPM-A008(1)
        9 x data receive point:
          dr_Ext_tAir: data-element=R_Ext_tAir.Ext_tAir
          dr_Ext_nEng: data-element=R_Ext_nEng.Ext_nEng
          dr_ExM_mfEgWoutEGR: data-element=R_ExM_mfEgWoutEGR.ExM_mfEgWoutEGR
          dr_FARSp_rMixtCylSp: data-element=R_FARSp_rMixtCylSp.FARSp_rMixtCylSp
          dr_ExM_tExMnfEstim: data-element=R_ExM_tExMnfEstim.ExM_tExMnfEstim
          dr_EngM_rAirLdCor: data-element=R_EngM_rAirLdCor.EngM_rAirLdCor
          dr_Ext_tCoMes: data-element=R_Ext_tCoMes.Ext_tCoMes
          dr_Veh_spdVeh: data-element=R_Veh_spdVeh.Veh_spdVeh
          dr_Ext_rSpdFanAct: data-element=R_Ext_rSpdFanAct.Ext_rSpdFanAct
        data send point ds_PhyMSI_tTrbCaseEstim: data-element=P_PhyMSI_tTrbCaseEstim.PhyMSI_tTrbCaseEstim
        data send point ds_PhyMSI_tExMnfEstim: data-element=P_PhyMSI_tExMnfEstim.PhyMSI_tExMnfEstim
        data send point ds_PhyMSI_pwrCylHdEstim: data-element=P_PhyMSI_pwrCylHdEstim.PhyMSI_pwrCylHdEstim
      RE_TPM_001_MSE: written-variable=[TPM_noAcvThermoProtDev, TPM_rAirLdReqRbl, TPM_mfAirScvLimMax, TPM_tRefTWCScvMax, TPM_bAcvProtExScv, TPM_tTWC, TPM_rAirLdReq, TPM_tExCurAcvThermoProtDev]  # 01552_11_02164-TPM-A001(0)
        data receive point dr_Ext_tAir: data-element=R_Ext_tAir.Ext_tAir
        data receive point dr_EOM_tiEngStop: data-element=R_EOM_tiEngStop.EOM_tiEngStop
        18 x data send point:
          ds_TPM_tTarAcvThermoProtDev: data-element=P_TPM_tTarAcvThermoProtDev.TPM_tTarAcvThermoProtDev
          ds_PhyMSI_tExMnfEstim: data-element=P_PhyMSI_tExMnfEstim.PhyMSI_tExMnfEstim
          ds_TPM_bAcvRichThermoProt: data-element=P_TPM_bAcvRichThermoProt.TPM_bAcvRichThermoProt
          ds_TPM_bInhOvbReq: data-element=P_TPM_bInhOvbReq.TPM_bInhOvbReq
          ds_TPM_tExReq: data-element=P_TPM_tExReq.TPM_tExReq
          ds_TPM_bAcvRichProtOxdTWC: data-element=P_TPM_bAcvRichProtOxdTWC.TPM_bAcvRichProtOxdTWC
          ds_TPM_bInhInjSelCutOff: data-element=P_TPM_bInhInjSelCutOff.TPM_bInhInjSelCutOff
          ds_TPM_bExThermoProt: data-element=P_TPM_bExThermoProt.TPM_bExThermoProt
          ds_TPM_bAirLdLimTExMgr: data-element=P_TPM_bAirLdLimTExMgr.TPM_bAirLdLimTExMgr
          ds_TPM_mfAirScvLimMaxCor: data-element=P_TPM_mfAirScvLimMaxCor.TPM_mfAirScvLimMaxCor
          ds_TPM_rMixtLimMaxAflScv: data-element=P_TPM_rMixtLimMaxAflScv.TPM_rMixtLimMaxAflScv
          ds_ExM_stO2HcStgTWC: data-element=P_ExM_stO2HcStgTWC.ExM_stO2HcStgTWC
          ds_PhyMSI_pCylMaxEstim: data-element=P_PhyMSI_pCylMaxEstim.PhyMSI_pCylMaxEstim
          ds_TPM_bRichLimScv: data-element=P_TPM_bRichLimScv.TPM_bRichLimScv
          ds_PhyMSI_pwrCylHdEstim: data-element=P_PhyMSI_pwrCylHdEstim.PhyMSI_pwrCylHdEstim
          ds_TPM_bInhInjCutOff: data-element=P_TPM_bInhInjCutOff.TPM_bInhInjCutOff
          ds_PhyMSI_tTrbCaseEstim: data-element=P_PhyMSI_tTrbCaseEstim.PhyMSI_tTrbCaseEstim
          ds_TPM_rLdProtExThermo: data-element=P_TPM_rLdProtExThermo.TPM_rLdProtExThermo
      RE_TPM_006_TEV: read-variable=[TPM_noAcvThermoProtDev, TPM_bAcvProtExScv, TPM_tExCurAcvThermoProtDev, TPM_rAirLdReq, TPM_rAirLdReqRbl]  # 01552_11_02164-TPM-A006(1)
        13 x data receive point:
          dr_FARSp_bThermoProtReqNotAuth: data-element=R_FARSp_bThermoProtReqNotAuth.FARSp_bThermoProtReqNotAuth
          dr_EngM_rAirLdCor: data-element=R_EngM_rAirLdCor.EngM_rAirLdCor
          dr_TPM_bAcvRichThermoProt: data-element=R_TPM_bAcvRichThermoProt.TPM_bAcvRichThermoProt
          dr_TPM_tTarAcvThermoProtDev: data-element=R_TPM_tTarAcvThermoProtDev.TPM_tTarAcvThermoProtDev
          dr_FARSp_rMixtCylSp: data-element=R_FARSp_rMixtCylSp.FARSp_rMixtCylSp
          dr_FARSp_bSatMaxRatMixt: data-element=R_FARSp_bSatMaxRatMixt.FARSp_bSatMaxRatMixt
          dr_ExM_tExStatAfs: data-element=R_ExM_tExStatAfs.ExM_tExStatAfs
          dr_EngMTrb_rLdMax: data-element=R_EngMTrb_rLdMax.EngMTrb_rLdMax
          dr_TPM_bAirLdLimTExMgr: data-element=R_TPM_bAirLdLimTExMgr.TPM_bAirLdLimTExMgr
          dr_ExM_mfEgTot: data-element=R_ExM_mfEgTot.ExM_mfEgTot
          dr_FARSp_rMixtThermoProtSp: data-element=R_FARSp_rMixtThermoProtSp.FARSp_rMixtThermoProtSp
          dr_TPM_bAcvRichProtOxdTWC: data-element=R_TPM_bAcvRichProtOxdTWC.TPM_bAcvRichProtOxdTWC
          dr_Ext_nEng: data-element=R_Ext_nEng.Ext_nEng
        data send point ds_TPM_tExReq: data-element=P_TPM_tExReq.TPM_tExReq
        sync call SC_FRM_bAcvTPMDecTMaxDev: operation=R_FRM_bAcvTPMDecTMaxDev.GetFunctionPermission
      RE_TPM_007_TEV: read-variable=[TPM_rAirLdReqRbl, TPM_bAcvProtExScv], written-variable=TPM_rAirLdReq  # 01552_11_02164-TPM-A007(1)
        10 x data receive point:
          dr_TPM_tExReq: data-element=R_TPM_tExReq.TPM_tExReq
          dr_ExM_mfEgTot: data-element=R_ExM_mfEgTot.ExM_mfEgTot
          dr_ExM_prm_facGas: data-element=R_ExM_prm_facGas.ExM_prm_facGas
          dr_ExM_facCorIgProtComp: data-element=R_ExM_facCorIgProtComp.ExM_facCorIgProtComp
          dr_IgSys_rStatIgSpEfc: data-element=R_IgSys_rStatIgSpEfc.IgSys_rStatIgSpEfc
          dr_TPM_bAirLdLimTExMgr: data-element=R_TPM_bAirLdLimTExMgr.TPM_bAirLdLimTExMgr
          dr_ExM_prm_facFlex: data-element=R_ExM_prm_facFlex.ExM_prm_facFlex
          dr_TPM_rAirLdReqGas: data-element=R_TPM_rAirLdReqGas.TPM_rAirLdReqGas
          dr_Ext_nEng: data-element=R_Ext_nEng.Ext_nEng
          dr_EngM_rAirLdCor: data-element=R_EngM_rAirLdCor.EngM_rAirLdCor
        data send point ds_TPM_rLdProtExThermo: data-element=P_TPM_rLdProtExThermo.TPM_rLdProtExThermo
      RE_TPM_009_DRE  # 01552_11_02164-TPM-A009(0)
        data receive point dr_EngM_rAirLdCor: data-element=R_EngM_rAirLdCor.EngM_rAirLdCor
        data receive point dr_Ext_nEng: data-element=R_Ext_nEng.Ext_nEng
        data send point ds_PhyMSI_pCylMaxEstim: data-element=P_PhyMSI_pCylMaxEstim.PhyMSI_pCylMaxEstim
  swc implementation Imp_TPM: programming-language=C, behavior=IB_TPM
    code-descriptors:
      code CodeDescriptor: type=SRC
        11 x xfile:
          TPM_nvm_h: url=TPM_nvm.h
          TPM_code_h: url=TPM_code.h
          TPM_code_c: url=TPM_code.c
          TPM_Library_c: url=TPM_Library.c
          TPM_MemMap_h: url=TPM_MemMap.h
          TPM_h: url=TPM.h
          TPM_calibrations_h: url=TPM_calibrations.h
          TPM_calibrations_c: url=TPM_calibrations.c
          TPM_nvm_c: url=TPM_nvm.c
          TPM_Library_h: url=TPM_Library.h
          TPM_c: url=TPM.c
package /Components/SWC_TPM/TPM_IRVDatatypes
  boolean type DT_TPM_bAcvProtExScv: base-type=boolean
  7 x integer type, all with lower-limit=0:
    DT_TPM_mfAirScvLimMax: base-type=uint16, upper-limit=65535
    DT_TPM_noAcvThermoProtDev: base-type=uint8, upper-limit=255
    DT_TPM_rAirLdReq: base-type=uint16, upper-limit=65535
    DT_TPM_rAirLdReqRbl: base-type=uint16, upper-limit=65535
    DT_TPM_tExCurAcvThermoProtDev: base-type=uint16, upper-limit=65535
    DT_TPM_tRefTWCScvMax: base-type=uint16, upper-limit=65535
    DT_TPM_tTWC: base-type=uint16, upper-limit=65535
